# MSS_CSI2RX_CTRL register map
Vendor: Texas Instruments
Peripheral module from a debugger description file (folder awr2x44p).
Registers are 32-bit, read-write, no defined reset value unless marked. A register's access mark holds for its fields unless they carry their own. Offsets are as the file gives them; lines under a group give offsets from that group; [hi:lo] are bit positions; {n}, {i} and the like mark numbered series; 'fields as' and 'values as' point back to an identical list; <NAME> marks a mode.

## MSS_CSI2RX_CTRL
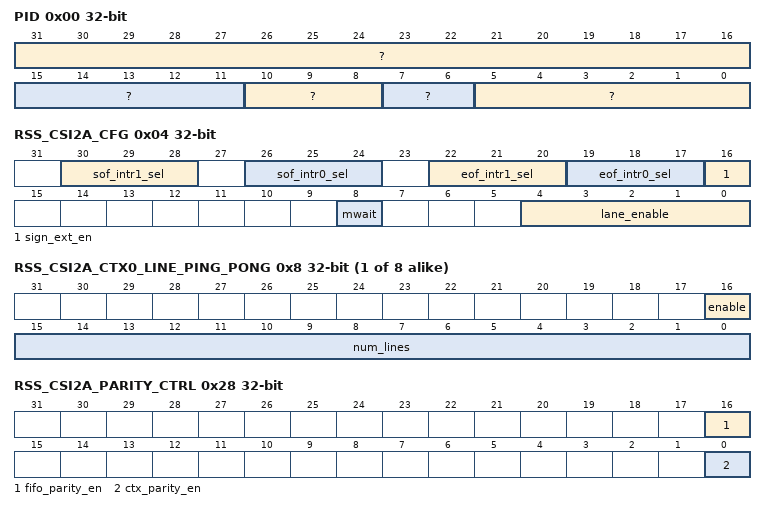
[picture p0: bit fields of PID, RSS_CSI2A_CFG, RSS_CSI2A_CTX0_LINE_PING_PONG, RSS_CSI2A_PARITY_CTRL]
0x00 PID ro
  [31:16] ?, [15:11] ?, [10:8] ?, [7:6] ?, [5:0] ?
0x04 RSS_CSI2A_CFG
  [30:28] sof_intr1_sel — Select the Start of Frame Contx to be sent as RCSS_CSI2A_SOF_INT1#br#Write 0 : Start of Frame for Context 0 will be propagated on this interrupt line#br#Write 7 : Start of Frame for Context 7 will be propagated on this interrupt line
  [26:24] sof_intr0_sel — Select the Start of Frame Contx to be sent as RCSS_CSI2A_SOF_INT0#br#Write 0 : Start of Frame for Context 0 will be propagated on this interrupt line#br#Write 7 : Start of Frame for Context 7 will be propagated on this interrupt line
  [22:20] eof_intr1_sel — Select the End of Frame Contx to be sent as RCSS_CSI2A_EOF_INT1#br#Write 0 : Start of Frame for Context 0 will be propagated on this interrupt line#br#Write 7 : Start of Frame for Context 7 will be propagated on this interrupt line
  [19:17] eof_intr0_sel — Select the End of Frame Contx to be sent as RCSS_CSI2A_EOF_INT0#br#Write 0 : Start of Frame for Context 0 will be propagated on this interrupt line#br#Write 7 : Start of Frame for Context 7 will be propagated on this interrupt line
  [16] sign_ext_en — Sign Extention Enable for CSI2 A
  [8] mwait — Power Idle Protocol related Mwait Port
  [4:0] lane_enable — Lane enable for CSI2 A
{0x8+4i} RSS_CSI2A_CTX{i}_LINE_PING_PONG (i=0..7)
  [16] enable — Enable line based ping pong toggle for Context {i}#br#0 : Diabled#br#1:Enabled
  [15:0] num_lines — Configure the number of lines for ping pong toggle for Context {i}
0x28 RSS_CSI2A_PARITY_CTRL
  [16] fifo_parity_en — Enable Parity for CSI2 FIFO Memory. Write 0x1 : Parity is enabled
  [0] ctx_parity_en — Enable Parity for CSI2 CTX Memory. Write 0x1 : Parity is enabled
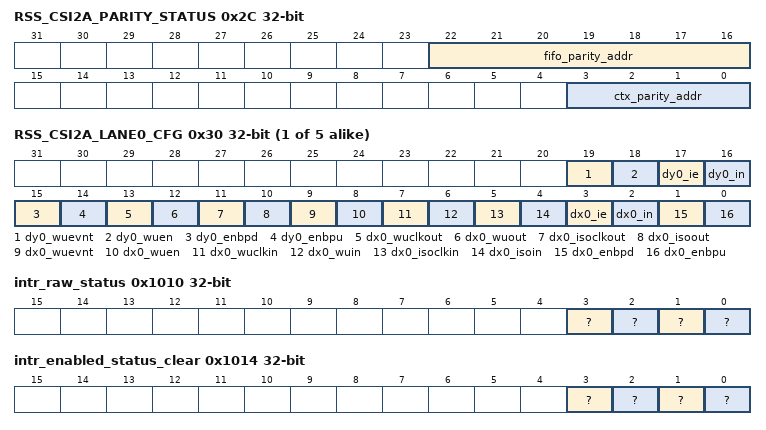
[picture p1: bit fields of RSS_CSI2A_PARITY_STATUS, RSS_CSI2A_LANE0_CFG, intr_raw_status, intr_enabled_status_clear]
0x2C RSS_CSI2A_PARITY_STATUS ro
  [22:16] fifo_parity_addr — CSI2 FIFO Memory Error Address at which Parity Error occurred
  [3:0] ctx_parity_addr — CSI2 CTX Memory Error Address at which Parity Error occurred
{0x30+4i} RSS_CSI2A_LANE{i}_CFG access per field (i=0..4)
  [19] dy{i}_wuevnt ro — Pad DY Wakeup Event
  [18] dy{i}_wuen rw — Pad DY Wakeup Enable
  [17] dy{i}_ie rw — Pad DY Input Buffer Enable
  [16] dy{i}_in ro — Pad DY Input
  [15] dy{i}_enbpd rw — Pad DY Enable Pull Down
  [14] dy{i}_enbpu rw — Pad DY Enable Pull Up
  [13] dx{i}_wuclkout ro — Pad DX Wakeup Clkout
  [12] dx{i}_wuout ro — Pad DX Wakeup Output
  [11] dx{i}_isoclkout ro — Pad DX Isosaltion Clkout
  [10] dx{i}_isoout ro — Pad DX Isosaltion Output
  [9] dx{i}_wuevnt ro — Pad DX Wakeup Event
  [8] dx{i}_wuen rw — Pad DX Wakeup Enable
  [7] dx{i}_wuclkin rw — Pad DX Wakeup Clkin
  [6] dx{i}_wuin rw — Pad DX Wakeup Input
  [5] dx{i}_isoclkin rw — Pad DX Isolation Clkin
  [4] dx{i}_isoin rw — Pad DX Isosaltion Input
  [3] dx{i}_ie rw — Pad DX Input Buffer Enable
  [2] dx{i}_in ro — Pad DX Input
  [1] dx{i}_enbpd rw — Pad DX Enable Pull Down
  [0] dx{i}_enbpu rw — Pad DX Enable Pull Up
0x44 RSS_CSI2A_FIFO_MEMINIT
  [0] start — Start Memory intialization of memory. Write 0x1 to start memory initilization. Write 0x0 after ensuring Memory intilization is in progress or has completed.
0x48 RSS_CSI2A_FIFO_MEMINIT_DONE
  [0] done — Status field. Read value 0x1 indicates previously triggered Memory intialization of memory is complte.#br#Write 0x1 to clear status.
0x4C RSS_CSI2A_FIFO_MEMINIT_STATUS ro
  [0] status — Status field. Read value 0x1 indicates previously triggered Memory intialization of memory is in progress.
0x50 RSS_CSI2A_CTX_MEMINIT
  fields as RSS_CSI2A_FIFO_MEMINIT
0x54 RSS_CSI2A_CTX_MEMINIT_DONE
  fields as RSS_CSI2A_FIFO_MEMINIT_DONE
0x58 RSS_CSI2A_CTX_MEMINIT_STATUS ro
  fields as RSS_CSI2A_FIFO_MEMINIT_STATUS
0x5C RSS_CSI_ACCESS_MODE
  [0] csi2a_sel — writing 1'b0 : ensures all the accesses from CSI2A are user-mode#br#writing 1'b1 : ensures all the accesses from CSI2A are privilege mode
0x1008 LOCK0_KICK0 — - KICK0 component
  [31:0] ?
0x100C LOCK0_KICK1 — - KICK1 component
  [31:0] ?
0x1010 intr_raw_status — Interrupt Raw Status/Set Register
  [3] ? — Proxy0 access violation error. Raw status is read. Write a 1 to set the status. Writing a 0 has no effect.
  [2] ? — Kick access violation error. Raw status is read. Write a 1 to set the status. Writing a 0 has no effect.
  [1] ? — Addressing violation error. Raw status is read. Write a 1 to set the status. Writing a 0 has no effect.
  [0] ? — Protection violation error. Raw status is read. Write a 1 to set the status. Writing a 0 has no effect.
0x1014 intr_enabled_status_clear — Interrupt Enabled Status/Clear register
  [3] ? — Proxy0 access violation error. Enabled status is read. Write a 1 to clear the status. Writing a 0 has no effect.
  [2] ? — Kick access violation error. Enabled status is read. Write a 1 to clear the status. Writing a 0 has no effect.
  [1] ? — Addressing violation error. Enabled status is read. Write a 1 to clear the status. Writing a 0 has no effect.
  [0] ? — Protection violation error. Enabled status is read. Write a 1 to clear the status. Writing a 0 has no effect.
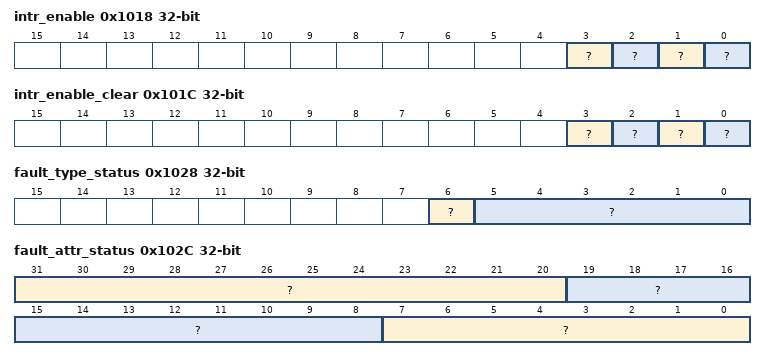
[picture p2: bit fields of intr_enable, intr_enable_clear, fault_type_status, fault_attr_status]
0x1018 intr_enable — Interrupt Enable register
  [3] ? — Proxy0 access violation error enable. Write a 1 to set the enable. Writing a 0 has no effect.
  [2] ? — Kick access violation error enable. Write a 1 to set the enable. Writing a 0 has no effect.
  [1] ? — Addressing violation error enable. Write a 1 to set the enable. Writing a 0 has no effect.
  [0] ? — Protection violation error enable. Write a 1 to set the enable. Writing a 0 has no effect.
0x101C intr_enable_clear — Interrupt Enable Clear register
  [3] ? — Proxy0 access violation error enable clear. Write a 1 to clear the enable. Writing a 0 has no effect.
  [2] ? — Kick access violation error enable clear. Write a 1 to clear the enable. Writing a 0 has no effect.
  [1] ? — Addressing violation error enable clear. Write a 1 to clear the enable. Writing a 0 has no effect.
  [0] ? — Protection violation error enable clear. Write a 1 to clear the enable. Writing a 0 has no effect.
0x1020 eoi
  [7:0] ? — EOI vector value. Write this with interrupt distribution value in the chip.
0x1024 fault_address ro
  [31:0] ? — Fault Address.
0x1028 fault_type_status ro
  [6] ? — Non-secure access.
  [5:0] ? — Fault Type #br# 10_0000 = Supervisor read fault - priv = 1 dir = 1 dtype != 1 #br# 01_0000 = Supervisor write fault - priv = 1 dir = 0 #br# 00_1000 = Supervisor execute fault - priv = 1 dir = 1 dtype = 1 #br# 00_0100 = User read fault - priv = 0 dir = 1 dtype = 1 #br# 00_0010 = User write fault - priv = 0 dir = 0 #br# 00_0001 = User execute fault - priv = 0 dir = 1 dtype = 1 #br# 00_0000 = No fault
0x102C fault_attr_status ro — Fault Attribute Status register
  [31:20] ? — XID.
  [19:8] ? — Route ID.
  [7:0] ? — Privilege ID.
0x1030 fault_clear wo
  [0] ? — Fault clear. Writing a 1 clears the current fault. Writing a 0 has no effect.
